# STM32C552 register map
File version: 2.1.0
CPU: CM33 r0p4, little endian, MPU, FPU, 4 interrupt priority bits
Registers are 32-bit, read-write, reset 0x0 unless marked. A register's access mark holds for its fields unless they carry their own. Offsets are from the block's base; [hi:lo] are bit positions; {n}, {i} and the like mark numbered series.

## TAMP — TAMP register block
Base 0x44007C00
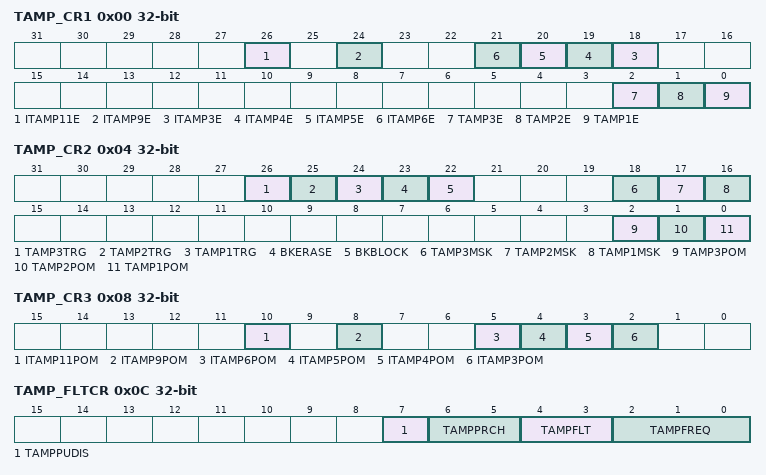
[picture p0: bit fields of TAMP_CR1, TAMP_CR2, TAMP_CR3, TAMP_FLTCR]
0x00 TAMP_CR1 — TAMP control register 1
  [26] ITAMP11E — Internal tamper 11 enable
    0=Internal tamper 11 disabled; 1=Internal tamper 11 enabled
  [24] ITAMP9E — Internal tamper 9 enable
    0=Internal tamper 9 disabled; 1=Internal tamper 9 enabled
  [n+15] ITAMP{n}E (n=3..6) — Internal tamper {n} enable
    0=Internal tamper {n} disabled; 1=Internal tamper {n} enabled
  [2] TAMP3E — Tamper detection on TAMP_IN3 enableless thansup>(1)less than/sup>
    0=Tamper detection on TAMP_IN3 is disabled; 1=Tamper detection on TAMP_IN3 is enabled
  [1] TAMP2E — Tamper detection on TAMP_IN2 enableless thansup>(1)less than/sup>
    0=Tamper detection on TAMP_IN2 is disabled; 1=Tamper detection on TAMP_IN2 is enabled
  [0] TAMP1E — Tamper detection on TAMP_IN1 enable
    0=Tamper detection on TAMP_IN1 is disabled; 1=Tamper detection on TAMP_IN1 is enabled
0x04 TAMP_CR2 — TAMP control register 2
  [26] TAMP3TRG — Active level for tamper 3 input
    0=If TAMPFLT different to 00 tamper 3 input staying low triggers a tamper detection event; 1=If TAMPFLT different to 00 tamper 3 input staying high triggers a tamper detection event
  [25] TAMP2TRG — Active level for tamper 2 input
    0=If TAMPFLT different to 00 tamper 2 input staying low triggers a tamper detection event; 1=If TAMPFLT different to 00 tamper 2 input staying high triggers a tamper detection event
  [24] TAMP1TRG — Active level for tamper 1 input
    0=If TAMPFLT different to 00 tamper 1 input staying low triggers a tamper detection event; 1=If TAMPFLT different to 00 tamper 1 input staying high triggers a tamper detection event
  [23] BKERASE wo — Backup registers and device secretsless thansup>(1)less than/sup> erase
  [22] BKBLOCK — Backup registers and device secretsless thansup>(1)less than/sup> access blocked
    0=backup registers and device secretsless thansup>(1)less than/sup> can be accessed if no tamper flag is set; 1=backup registers and device secretsless thansup>(1)less than/sup> cannot be accessed
  [18] TAMP3MSK — Tamper 3 mask
    0=Tamper 3 event generates a trigger event and TAMP3F must be cleared by software to allow next tamper event detection; 1=Tamper 3 event generates a trigger event
  [17] TAMP2MSK — Tamper 2 mask
    0=Tamper 2 event generates a trigger event and TAMP2F must be cleared by software to allow next tamper event detection; 1=Tamper 2 event generates a trigger event
  [16] TAMP1MSK — Tamper 1 mask
    0=Tamper 1 event generates a trigger event and TAMP1F must be cleared by software to allow next tamper event detection; 1=Tamper 1 event generates a trigger event
  [2] TAMP3POM — Tamper 3 potential mode
    0=Tamper 3 event detection is in confirmed modeless thansup>(1)less than/sup>; 1=Tamper 3 event detection is in potential modeless thansup>(2)less than/sup>
  [1] TAMP2POM — Tamper 2 potential mode
    0=Tamper 2 event detection is in confirmed modeless thansup>(1)less than/sup>; 1=Tamper 2 event detection is in potential modeless thansup>(2)less than/sup>
  [0] TAMP1POM — Tamper 1 potential mode
    0=Tamper 1 event detection is in confirmed mode; 1=Tamper 1 event detection is in potential mode
0x08 TAMP_CR3 — TAMP control register 3
  [10] ITAMP11POM — Internal tamper 11 potential mode
    0=Internal tamper 11 event detection is in confirmed modeless thansup>(1)less than/sup>; 1=Internal tamper 11 event detection is in potential modeless thansup>(2)less than/sup>
  [8] ITAMP9POM — Internal tamper 9 potential mode
    0=Internal tamper 9 event detection is in confirmed modeless thansup>(1)less than/sup>; 1=Internal tamper 9 event detection is in potential modeless thansup>(2)less than/sup>
  [5] ITAMP6POM — Internal tamper 6 potential mode
    0=Internal tamper 6 event detection is in confirmed mode; 1=Internal tamper 6 event detection is in potential mode
  [4] ITAMP5POM — Internal tamper 5 potential mode
    0=Internal tamper 5 event detection is in confirmed modeless thansup>(1)less than/sup>; 1=Internal tamper 5 event detection is in potential modeless thansup>(2)less than/sup>
  [3] ITAMP4POM — Internal tamper 4 potential mode
    0=Internal tamper 4 event detection is in confirmed modeless thansup>(1)less than/sup>; 1=Internal tamper 4 event detection is in potential modeless thansup>(2)less than/sup>
  [2] ITAMP3POM — Internal tamper 3 potential mode
    0=Internal tamper 3 event detection is in confirmed modeless thansup>(1)less than/sup>; 1=Internal tamper 3 event detection is in potential modeless thansup>(2)less than/sup>
0x0C TAMP_FLTCR — TAMP filter control register
  [7] TAMPPUDIS — TAMP_INx pull-up disable
    0=Precharge TAMP_INx pins before sampling (enable internal pull-up); 1=Disable precharge of TAMP_INx pins
  [6:5] TAMPPRCH — TAMP_INx precharge duration
    0=1 RTCCLK cycle; 1=2 RTCCLK cycles; 2=4 RTCCLK cycles; 3=8 RTCCLK cycles
  [4:3] TAMPFLT — TAMP_INx filter count
    0=Tamper event is activated on edge of TAMP_INx input transitions to the active level (no internal pull-up on TAMP_INx input); 1=Tamper event is activated after 2 consecutive samples at the active level; 2=Tamper event is activated after 4 consecutive samples at the active level; 3=Tamper event is activated after 8 consecutive samples at the active level
  [2:0] TAMPFREQ — Tamper sampling frequency
    0=RTCCLK / 32768 (1Hz when RTCCLK = 32768Hz); 1=RTCCLK / 16384 (2Hz when RTCCLK = 32768Hz); 2=RTCCLK / 8192 (4Hz when RTCCLK = 32768Hz); 3=RTCCLK / 4096 (8Hz when RTCCLK = 32768Hz); 4=RTCCLK / 2048 (16Hz when RTCCLK = 32768Hz); 5=RTCCLK / 1024 (32Hz when RTCCLK = 32768Hz); 6=RTCCLK / 512 (64Hz when RTCCLK = 32768Hz); 7=RTCCLK / 256 (128Hz when RTCCLK = 32768Hz)
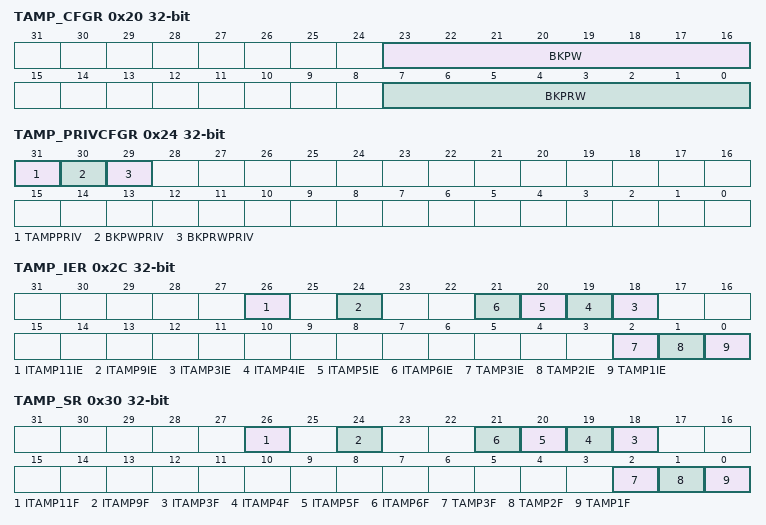
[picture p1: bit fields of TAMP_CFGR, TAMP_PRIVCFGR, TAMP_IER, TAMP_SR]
0x20 TAMP_CFGR — TAMP configuration register
  [23:16] BKPW — Backup registers write protection offset
  [7:0] BKPRW — Backup registers read/write protection offset
0x24 TAMP_PRIVCFGR — TAMP privilege configuration register
  [31] TAMPPRIV — Tamper privilege protection (excluding backup registers)
    0=Tamper configuration and interrupt can be written with privileged or unprivileged access; 1=Tamper configuration and interrupt can be written only with privileged access
  [30] BKPWPRIV — Backup registers zone 2 privilege protection
    0=Backup registers zone 2 can be written with privileged or unprivileged access; 1=Backup registers zone 2 can be written only with privileged access
  [29] BKPRWPRIV — Backup registers zone 1 privilege protection
    0=Backup registers zone 1 can be read and written with privileged or unprivileged access; 1=Backup registers zone 1 can be read and written only with privileged access
0x2C TAMP_IER — TAMP interrupt enable register
  [26] ITAMP11IE — Internal tamper 11 interrupt enable
    0=Internal tamper 11 interrupt disabled; 1=Internal tamper 11 interrupt enabled
  [24] ITAMP9IE — Internal tamper 9 interrupt enable
    0=Internal tamper 9 interrupt disabled; 1=Internal tamper 9 interrupt enabled
  [n+15] ITAMP{n}IE (n=3..6) — Internal tamper {n} interrupt enable
    0=Internal tamper {n} interrupt disabled; 1=Internal tamper {n} interrupt enabled
  [2] TAMP3IE — Tamper 3 interrupt enable
    0=Tamper 3 interrupt disabled; 1=Tamper 3 interrupt enabled
  [1] TAMP2IE — Tamper 2 interrupt enable
    0=Tamper 2 interrupt disabled; 1=Tamper 2 interrupt enabled
  [0] TAMP1IE — Tamper 1 interrupt enable
    0=Tamper 1 interrupt disabled; 1=Tamper 1 interrupt enabled
0x30 TAMP_SR ro — TAMP status register
  [26] ITAMP11F — Internal tamper 11 flag
  [24] ITAMP9F — Internal tamper 9 flag
  [n+15] ITAMP{n}F (n=3..6) — Internal tamper {n} flag
  [2] TAMP3F — TAMP3 detection flag
  [1] TAMP2F — TAMP2 detection flag
  [0] TAMP1F — TAMP1 detection flag
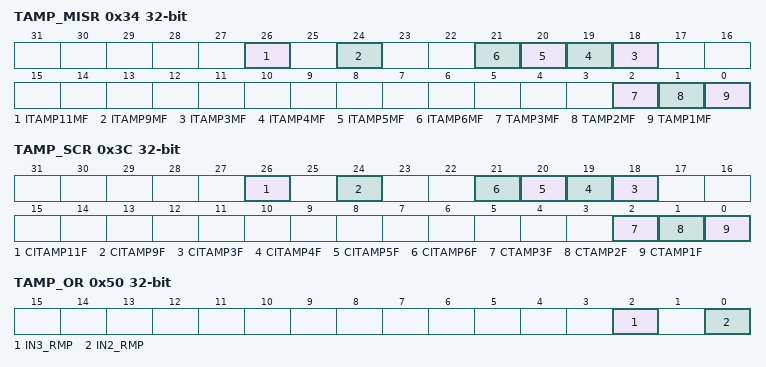
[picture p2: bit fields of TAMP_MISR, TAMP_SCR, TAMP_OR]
0x34 TAMP_MISR ro — TAMP masked interrupt status register
  [26] ITAMP11MF — internal tamper 11 interrupt masked flag
  [24] ITAMP9MF — internal tamper 9 interrupt masked flag
  [n+15] ITAMP{n}MF (n=3..6) — Internal tamper {n} interrupt masked flag
  [2] TAMP3MF — TAMP3 interrupt masked flag
  [1] TAMP2MF — TAMP2 interrupt masked flag
  [0] TAMP1MF — TAMP1 interrupt masked flag
0x3C TAMP_SCR wo — TAMP status clear register
  [26] CITAMP11F — Clear ITAMP11 detection flag
  [24] CITAMP9F — Clear ITAMP9 detection flag
  [n+15] CITAMP{n}F (n=3..6) — Clear ITAMP{n} detection flag
  [2] CTAMP3F — Clear TAMP3 detection flag
  [1] CTAMP2F — Clear TAMP2 detection flag
  [0] CTAMP1F — Clear TAMP1 detection flag
0x50 TAMP_OR — TAMP option register
  [2] IN3_RMP — TAMP_IN3 pin select
    0=TAMP_IN3 is mapped on PA1; 1=TAMP_IN3 is mapped on PA2
  [0] IN2_RMP — TAMP_IN2 pin select
    0=TAMP_IN2 is mapped on PA0; 1=TAMP_IN2 is mapped on PC1
{0x100+4i} TAMP_BKP{i}R (i=0..31) — TAMP backup {i} register
  [31:0] BKP — The application can write or read data to and from these registers.
